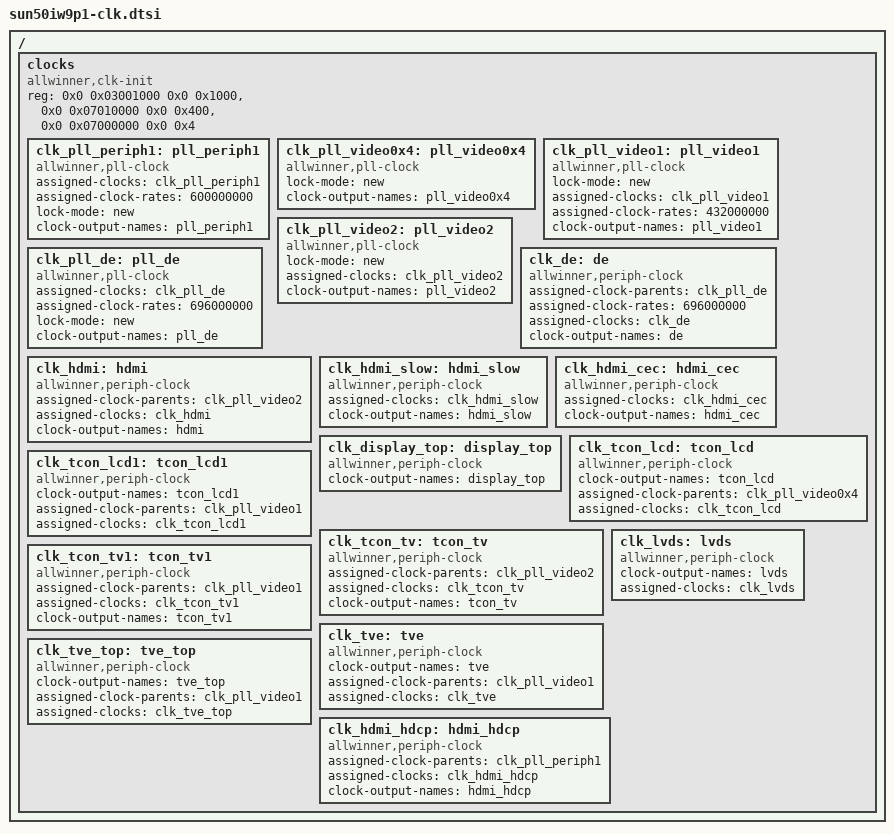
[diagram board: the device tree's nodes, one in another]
/{
clocks {
	compatible = "allwinner,clk-init";
	device_type = "clocks";
	#address-cells = <2>;
	#size-cells = <2>;
	ranges;
	reg = <0x0 0x03001000 0x0 0x1000>,	/*cpux space*/
	      <0x0 0x07010000 0x0 0x400>,	/*cpus space*/
	      <0x0 0x07000000 0x0 0x4>;

		clk_pll_periph1: pll_periph1 {
			#clock-cells = <0>;
			compatible = "allwinner,pll-clock";
			assigned-clocks = <&clk_pll_periph1>;
			assigned-clock-rates = <600000000>;
			lock-mode = "new";
			clock-output-names = "pll_periph1";
		};
		clk_pll_video0x4: pll_video0x4 {
			#clock-cells = <0>;
			compatible = "allwinner,pll-clock";
			lock-mode = "new";
			clock-output-names = "pll_video0x4";
		};
		clk_pll_video1: pll_video1 {
			#clock-cells = <0>;
			compatible = "allwinner,pll-clock";
			lock-mode = "new";
			assigned-clocks = <&clk_pll_video1>;
			assigned-clock-rates = <432000000>;
			clock-output-names = "pll_video1";
		};
		clk_pll_video2: pll_video2 {
			#clock-cells = <0>;
			compatible = "allwinner,pll-clock";
			lock-mode = "new";
			assigned-clocks = <&clk_pll_video2>;
			/*assigned-clock-rates = <432000000>;*/
			clock-output-names = "pll_video2";
		};
		clk_pll_de: pll_de {
			#clock-cells = <0>;
			compatible = "allwinner,pll-clock";
			assigned-clocks = <&clk_pll_de>;
			assigned-clock-rates = <696000000>;
			lock-mode = "new";
			clock-output-names = "pll_de";
		};
		clk_de: de {
			#clock-cells = <0>;
			compatible = "allwinner,periph-clock";
			assigned-clock-parents = <&clk_pll_de>;
			assigned-clock-rates = <696000000>;
			assigned-clocks = <&clk_de>;
			clock-output-names = "de";
		};
		clk_hdmi: hdmi {
			#clock-cells = <0>;
			compatible = "allwinner,periph-clock";
			assigned-clock-parents = <&clk_pll_video2>;
			assigned-clocks = <&clk_hdmi>;
			clock-output-names = "hdmi";
		};
		clk_hdmi_slow: hdmi_slow {
			#clock-cells = <0>;
			compatible = "allwinner,periph-clock";
			assigned-clocks = <&clk_hdmi_slow>;
			clock-output-names = "hdmi_slow";
		};
		clk_hdmi_cec: hdmi_cec {
			#clock-cells = <0>;
			compatible = "allwinner,periph-clock";
			assigned-clocks = <&clk_hdmi_cec>;
			clock-output-names = "hdmi_cec";
		};
		clk_display_top: display_top {
			#clock-cells = <0>;
			compatible = "allwinner,periph-clock";
			clock-output-names = "display_top";
		};
		clk_tcon_lcd: tcon_lcd {
			#clock-cells = <0>;
			compatible = "allwinner,periph-clock";
			clock-output-names = "tcon_lcd";
			assigned-clock-parents = <&clk_pll_video0x4>;
			assigned-clocks = <&clk_tcon_lcd>;
		};
		clk_tcon_lcd1: tcon_lcd1 {
			#clock-cells = <0>;
			compatible = "allwinner,periph-clock";
			clock-output-names = "tcon_lcd1";
			assigned-clock-parents = <&clk_pll_video1>;
			assigned-clocks = <&clk_tcon_lcd1>;
		};
		clk_tcon_tv: tcon_tv {
			#clock-cells = <0>;
			compatible = "allwinner,periph-clock";
			assigned-clock-parents = <&clk_pll_video2>;
			assigned-clocks = <&clk_tcon_tv>;
			clock-output-names = "tcon_tv";
		};
		clk_tcon_tv1: tcon_tv1 {
			#clock-cells = <0>;
			compatible = "allwinner,periph-clock";
			assigned-clock-parents = <&clk_pll_video1>;
			assigned-clocks = <&clk_tcon_tv1>;
			clock-output-names = "tcon_tv1";
		};
		clk_lvds: lvds {
			#clock-cells = <0>;
			compatible = "allwinner,periph-clock";
			clock-output-names = "lvds";
			assigned-clocks = <&clk_lvds>;
		};
		clk_tve: tve {
			#clock-cells = <0>;
			compatible = "allwinner,periph-clock";
			clock-output-names = "tve";
			assigned-clock-parents = <&clk_pll_video1>;
			assigned-clocks = <&clk_tve>;
		};
		clk_tve_top: tve_top {
			#clock-cells = <0>;
			compatible = "allwinner,periph-clock";
			clock-output-names = "tve_top";
			assigned-clock-parents = <&clk_pll_video1>;
			assigned-clocks = <&clk_tve_top>;
		};
		clk_hdmi_hdcp: hdmi_hdcp {
			#clock-cells = <0>;
			compatible = "allwinner,periph-clock";
			assigned-clock-parents = <&clk_pll_periph1>;
			assigned-clocks = <&clk_hdmi_hdcp>;
			clock-output-names = "hdmi_hdcp";
		};
	};
};
